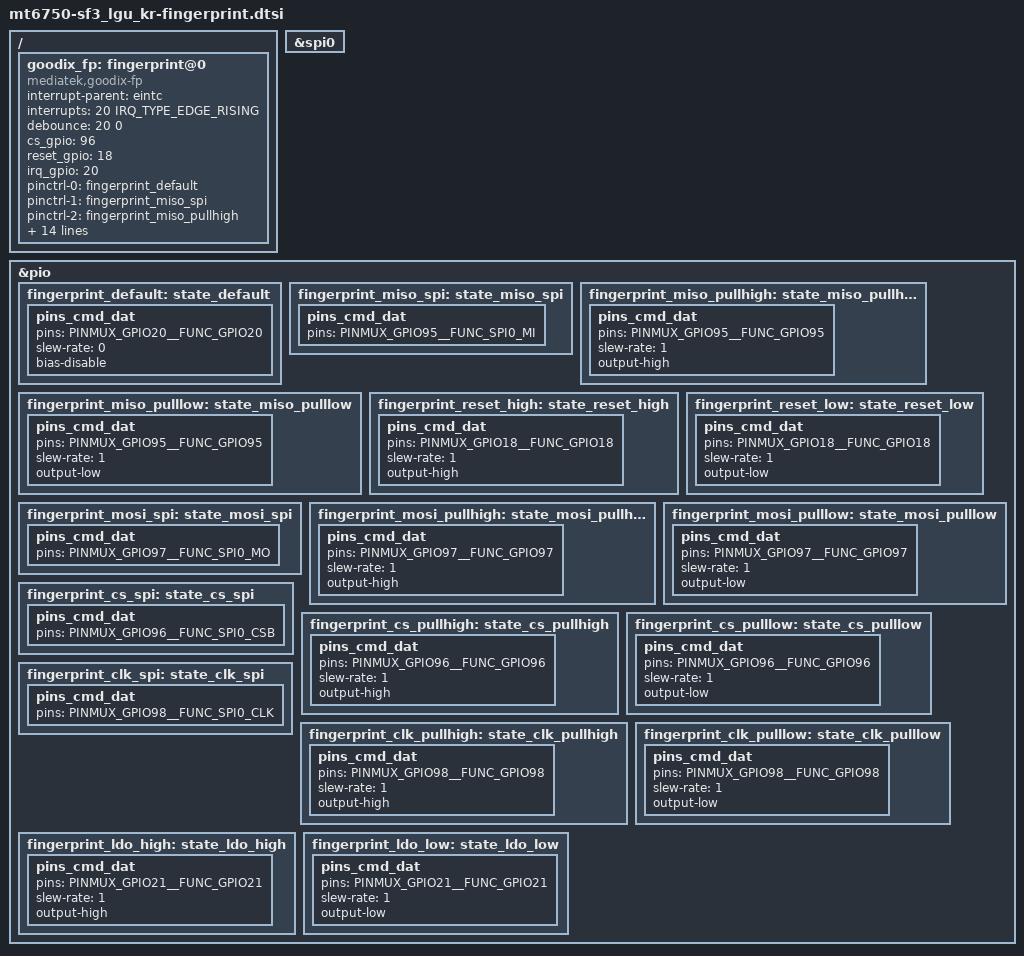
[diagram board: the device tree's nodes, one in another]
/*
 * LG Electronics SF3 fingerprint device tree source
 *
 * Copyright (c) 2016 LG Electronics Co., Ltd.
 *              http://www.lge.com
 *
 */
/{
	goodix_fp: fingerprint@0 {
		compatible = "mediatek,goodix-fp";
		interrupt-parent = <&eintc>;
		interrupts = <20 IRQ_TYPE_EDGE_RISING>;
		debounce = <20 0>;
		cs_gpio = <96>;
		reset_gpio = <18>;
		irq_gpio = <20>;
		status = "okay";

		pinctrl-names = "default", "miso_spi", "miso_pullhigh", "miso_pulllow", "reset_high", "reset_low","mosi_spi","mosi_pullhigh","mosi_pulllow","cs_spi","cs_pullhigh","cs_pulllow","clk_spi","clk_pullhigh","clk_pulllow", "ldo_high", "ldo_low";
		pinctrl-0 = <&fingerprint_default>;
		pinctrl-1 = <&fingerprint_miso_spi>;
		pinctrl-2 = <&fingerprint_miso_pullhigh>;
		pinctrl-3 = <&fingerprint_miso_pulllow>;
		pinctrl-4 = <&fingerprint_reset_high>;
		pinctrl-5 = <&fingerprint_reset_low>;
		pinctrl-6 = <&fingerprint_mosi_spi>;
		pinctrl-7 = <&fingerprint_mosi_pullhigh>;
		pinctrl-8 = <&fingerprint_mosi_pulllow>;
		pinctrl-9 = <&fingerprint_cs_spi>;
		pinctrl-10 = <&fingerprint_cs_pullhigh>;
		pinctrl-11 = <&fingerprint_cs_pulllow>;
		pinctrl-12 = <&fingerprint_clk_spi>;
		pinctrl-13 = <&fingerprint_clk_pullhigh>;
		pinctrl-14 = <&fingerprint_clk_pulllow>;
		pinctrl-15 = <&fingerprint_ldo_high>;
		pinctrl-16 = <&fingerprint_ldo_low>;
	};
};

&spi0 {
	#address-cells = <1>;
	#size-cells = <0>;

	#include "../gf3208.dtsi"
};

&pio {
	fingerprint_default: state_default {
		pins_cmd_dat {
			pins = <PINMUX_GPIO20__FUNC_GPIO20>;
			slew-rate = <0>;
			bias-disable;
		};
	};

	fingerprint_miso_spi: state_miso_spi {
		pins_cmd_dat {
			pins = <PINMUX_GPIO95__FUNC_SPI0_MI>;
		};
	};

	fingerprint_miso_pullhigh: state_miso_pullhigh {
		pins_cmd_dat {
			pins = <PINMUX_GPIO95__FUNC_GPIO95>;
			slew-rate = <1>;
			output-high;
		};
	};

	fingerprint_miso_pulllow: state_miso_pulllow {
		pins_cmd_dat {
			pins = <PINMUX_GPIO95__FUNC_GPIO95>;
			slew-rate = <1>;
			output-low;
		};
	};

	fingerprint_reset_high: state_reset_high {
		pins_cmd_dat {
			pins = <PINMUX_GPIO18__FUNC_GPIO18>;
			slew-rate = <1>;
			output-high;
		};
	};

	fingerprint_reset_low: state_reset_low {
		pins_cmd_dat {
			pins = <PINMUX_GPIO18__FUNC_GPIO18>;
			slew-rate = <1>;
			output-low;
		};
	};

	fingerprint_mosi_spi: state_mosi_spi {
		pins_cmd_dat {
			pins = <PINMUX_GPIO97__FUNC_SPI0_MO>;
		};
	};
	fingerprint_mosi_pullhigh: state_mosi_pullhigh {
		pins_cmd_dat {
			pins = <PINMUX_GPIO97__FUNC_GPIO97>;
			slew-rate = <1>;
			output-high;
		};
	};

	fingerprint_mosi_pulllow: state_mosi_pulllow {
		pins_cmd_dat {
			pins = <PINMUX_GPIO97__FUNC_GPIO97>;
			slew-rate = <1>;
			output-low;
		};
	};
	fingerprint_cs_spi: state_cs_spi {
		pins_cmd_dat {
			pins = <PINMUX_GPIO96__FUNC_SPI0_CSB>;
		};
	};

	fingerprint_cs_pullhigh: state_cs_pullhigh {
		pins_cmd_dat {
			pins = <PINMUX_GPIO96__FUNC_GPIO96>;
			slew-rate = <1>;
			output-high;
		};
	};

	fingerprint_cs_pulllow: state_cs_pulllow {
		pins_cmd_dat {
			pins = <PINMUX_GPIO96__FUNC_GPIO96>;
			slew-rate = <1>;
			output-low;
		};
	};

	fingerprint_clk_spi: state_clk_spi {
		pins_cmd_dat {
			pins = <PINMUX_GPIO98__FUNC_SPI0_CLK>;
		};
	};
	fingerprint_clk_pullhigh: state_clk_pullhigh {
		pins_cmd_dat {
			pins = <PINMUX_GPIO98__FUNC_GPIO98>;
			slew-rate = <1>;
			output-high;
		};
	};

	fingerprint_clk_pulllow: state_clk_pulllow {
		pins_cmd_dat {
			pins = <PINMUX_GPIO98__FUNC_GPIO98>;
			slew-rate = <1>;
			output-low;
		};
	};

	fingerprint_ldo_high: state_ldo_high {
		pins_cmd_dat {
			pins = <PINMUX_GPIO21__FUNC_GPIO21>;
			slew-rate = <1>;
			output-high;
		};
	};

	fingerprint_ldo_low: state_ldo_low {
		pins_cmd_dat {
			pins = <PINMUX_GPIO21__FUNC_GPIO21>;
			slew-rate = <1>;
			output-low;
		};
	};
};
